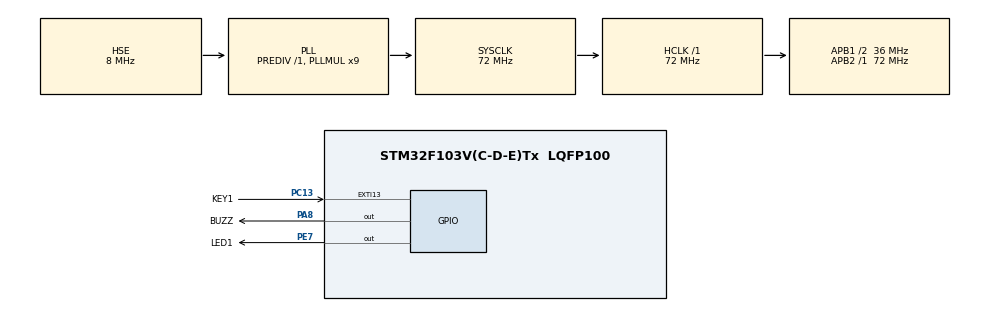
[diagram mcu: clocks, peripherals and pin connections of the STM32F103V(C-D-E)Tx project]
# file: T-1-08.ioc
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Mcu.Family=STM32F1
Mcu.Name=STM32F103V(C-D-E)Tx
Mcu.Package=LQFP100
NVIC.EXTI15_10_IRQn=true\:0\:0\:false\:false\:true\:true\:true
NVIC.PriorityGroup=NVIC_PRIORITYGROUP_4
OSC_IN.Mode=HSE-External-Oscillator
OSC_IN.Signal=RCC_OSC_IN
OSC_OUT.Mode=HSE-External-Oscillator
OSC_OUT.Signal=RCC_OSC_OUT
PA13.Mode=Serial_Wire
PA13.Signal=SYS_JTMS-SWDIO
PA14.Mode=Serial_Wire
PA14.Signal=SYS_JTCK-SWCLK
PA8.GPIO_Label=BUZZ
PA8.GPIO_Speed=GPIO_SPEED_FREQ_HIGH
PA8.PinState=GPIO_PIN_RESET
PA8.Signal=GPIO_Output
PC13-TAMPER-RTC.GPIO_Label=KEY1
PC13-TAMPER-RTC.GPIO_ModeDefaultEXTI=GPIO_MODE_IT_FALLING
PC13-TAMPER-RTC.GPIO_PuPd=GPIO_PULLUP
PC13-TAMPER-RTC.Signal=GPXTI13
PC14-OSC32_IN.Mode=LSE-External-Oscillator
PC14-OSC32_IN.Signal=RCC_OSC32_IN
PC15-OSC32_OUT.Mode=LSE-External-Oscillator
PC15-OSC32_OUT.Signal=RCC_OSC32_OUT
PE7.GPIO_Label=LED1
PE7.GPIO_ModeDefaultOutputPP=GPIO_MODE_OUTPUT_PP
PE7.GPIO_Speed=GPIO_SPEED_FREQ_HIGH
PE7.PinState=GPIO_PIN_SET
PE7.Signal=GPIO_Output
ProjectManager.HeapSize=0x200
ProjectManager.StackSize=0x400
ProjectManager.TargetToolchain=MDK-ARM V5
RCC.AHBFreq_Value=72000000
RCC.APB1CLKDivider=RCC_HCLK_DIV2
RCC.APB1Freq_Value=36000000
RCC.APB1TimFreq_Value=72000000
RCC.APB2Freq_Value=72000000
RCC.APB2TimFreq_Value=72000000
RCC.HCLKFreq_Value=72000000
RCC.PLLMUL=RCC_PLL_MUL9
RCC.PLLSourceVirtual=RCC_PLLSOURCE_HSE
RCC.SYSCLKFreq_VALUE=72000000
RCC.SYSCLKSource=RCC_SYSCLKSOURCE_PLLCLK
RCC.USBFreq_Value=72000000
board=custom

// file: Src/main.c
/* USER CODE BEGIN Header */
/**
  ******************************************************************************
  * @file           : main.c
  * @brief          : Main program body
  ******************************************************************************
  * @attention
  *
  * <h2><center>&copy; Copyright (c) 2022 STMicroelectronics.
  * All rights reserved.</center></h2>
  *
  * This software component is licensed by ST under BSD 3-Clause license,
  * the "License"; You may not use this file except in compliance with the
  * License. You may obtain a copy of the License at:
  *                        opensource.org/licenses/BSD-3-Clause
  *
  ******************************************************************************
  */
/* USER CODE END Header */

#include "main.h"
#include "gpio.h"

/* USER CODE BEGIN PV */
uint8_t Key_Flag=0;
uint8_t Buzz_Count=0;
/* USER CODE END PV */

void SystemClock_Config(void);
/* USER CODE BEGIN PFP */
			/****请在以下指定位置添加功能代码1***/
			//功能：声明蜂鸣器函数
			/****添加代码1开始***/
void BUZZ(void);
			/****添加代码1结束***/
/* USER CODE END PFP */

int main(void)
{

  /* MCU Configuration--------------------------------------------------------*/

  /* Reset of all peripherals, Initializes the Flash interface and the Systick. */
  HAL_Init();

  /* Configure the system clock */
  SystemClock_Config();

  /* Initialize all configured peripherals */
  MX_GPIO_Init();

  /* Infinite loop */
  /* USER CODE BEGIN WHILE */
  while (1)
  {
		if(Key_Flag == 1)
		{
			/****请在以下指定位置添加功能代码2***/
			//功能：调用蜂鸣器函数
			/****添加代码2开始***/
		 BUZZ();
			/****添加代码2结束***/
			if(Buzz_Count ==200)
				{
			/****请在以下指定位置添加功能代码3***/
			//功能：1、LED1电平反转
			//		  2、Buzz_Count计数值清零
			/****添加代码3开始***/
				HAL_GPIO_TogglePin (LED1_GPIO_Port ,LED1_Pin );
					Buzz_Count =0;
			/****添加代码3结束***/
				}
		}
		else
			HAL_GPIO_WritePin (GPIOE ,LED1_Pin,GPIO_PIN_SET );
    /* USER CODE END WHILE */

  }
}

void SystemClock_Config(void)
{
  RCC_OscInitTypeDef RCC_OscInitStruct = {0};
  RCC_ClkInitTypeDef RCC_ClkInitStruct = {0};

  /** Initializes the CPU, AHB and APB busses clocks
  */
  RCC_OscInitStruct.OscillatorType = RCC_OSCILLATORTYPE_HSE;
  RCC_OscInitStruct.HSEState = RCC_HSE_ON;
  RCC_OscInitStruct.HSEPredivValue = RCC_HSE_PREDIV_DIV1;
  RCC_OscInitStruct.HSIState = RCC_HSI_ON;
  RCC_OscInitStruct.PLL.PLLState = RCC_PLL_ON;
  RCC_OscInitStruct.PLL.PLLSource = RCC_PLLSOURCE_HSE;
  RCC_OscInitStruct.PLL.PLLMUL = RCC_PLL_MUL9;
  if (HAL_RCC_OscConfig(&RCC_OscInitStruct) != HAL_OK)
  {
    Error_Handler();
  }
  /** Initializes the CPU, AHB and APB busses clocks
  */
  RCC_ClkInitStruct.ClockType = RCC_CLOCKTYPE_HCLK|RCC_CLOCKTYPE_SYSCLK
                              |RCC_CLOCKTYPE_PCLK1|RCC_CLOCKTYPE_PCLK2;
  RCC_ClkInitStruct.SYSCLKSource = RCC_SYSCLKSOURCE_PLLCLK;
  RCC_ClkInitStruct.AHBCLKDivider = RCC_SYSCLK_DIV1;
  RCC_ClkInitStruct.APB1CLKDivider = RCC_HCLK_DIV2;
  RCC_ClkInitStruct.APB2CLKDivider = RCC_HCLK_DIV1;

  if (HAL_RCC_ClockConfig(&RCC_ClkInitStruct, FLASH_LATENCY_2) != HAL_OK)
  {
    Error_Handler();
  }
}

/* USER CODE BEGIN 4 */
void BUZZ(void)
{
			/****请在以下指定位置添加功能代码4***/
			//功能：1、Buzz_Count计数值自增；
			//      2、蜂鸣器以500HZ频率鸣叫。
			/****添加代码开始4***/
 Buzz_Count ++;
	HAL_GPIO_TogglePin (BUZZ_GPIO_Port ,BUZZ_Pin );
	HAL_Delay (1);

			/****添加代码结束4***/
}
			/****请在以下指定位置添加功能代码5***/
			//功能：找到外部中断函数EXTI15_10_IRQHandler()所对应的回调函数，并改写，实现按键标志位Key_Flag取反。
			/****添加代码5开始***/
void HAL_GPIO_EXTI_Callback(uint16_t GPIO_Pin)
{
	Key_Flag =! Key_Flag;
}

			/****添加代码5结束***/
/* USER CODE END 4 */

void Error_Handler(void)
{
}

/************************ (C) COPYRIGHT STMicroelectronics *****END OF FILE****/
